# BlueNRG_LP register map
File version: 1.0
CPU: CM0+ r0p0, little endian, no MPU, no FPU, 2 interrupt priority bits
Registers are 32-bit, read-write, reset 0x0 unless marked. A register's access mark holds for its fields unless they carry their own. Offsets are from the block's base; [hi:lo] are bit positions; {n}, {i} and the like mark numbered series.

## IWDG — Independent watchdog
Base 0x40003000
0x00 KR wo — Key register
  [15:0] KEY — Key value (write only, read 0x0000)
0x04 PR — Prescaler register
  [2:0] PR — Prescaler divider
0x08 RLR reset 0xFFF — Reload register
  [11:0] RL — Watchdog counter reload value
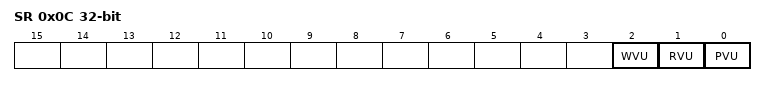
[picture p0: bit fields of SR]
0x0C SR ro — Status register
  [2] WVU — Watchdog counter window prescaler update
  [1] RVU — Watchdog counter reload prescaler update
  [0] PVU — Watchdog prescaler prescaler update
0x10 WINR reset 0xFFF — Window register
  [11:0] WIN — Watchdog counter window value

## LPUART1 — Universal synchronous asynchronous receiver transmitter
Base 0x41005000
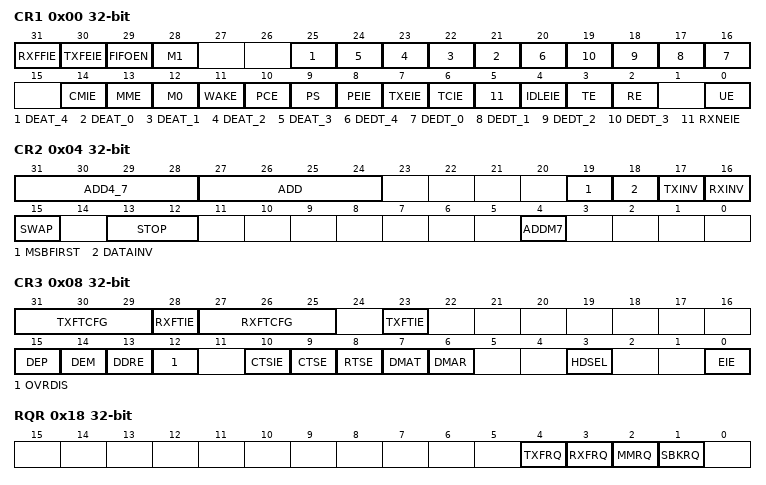
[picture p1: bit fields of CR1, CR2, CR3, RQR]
0x00 CR1 — Control register 1
  [31] RXFFIE
  [30] TXFEIE
  [29] FIFOEN
  [28] M1 — Word length
  [25] DEAT_4 — Driver Enable assertion time
  [n+21] DEAT_{n} (n=0..3)
  [20] DEDT_4 — Driver Enable de-assertion time
  [n+16] DEDT_{n} (n=0..3)
  [14] CMIE — Character match interrupt enable
  [13] MME — Mute mode enable
  [12] M0 — Word length
  [11] WAKE — Receiver wakeup method
  [10] PCE — Parity control enable
  [9] PS — Parity selection
  [8] PEIE — PE interrupt enable
  [7] TXEIE — interrupt enable
  [6] TCIE — Transmission complete interrupt enable
  [5] RXNEIE — RXNE interrupt enable
  [4] IDLEIE — IDLE interrupt enable
  [3] TE — Transmitter enable
  [2] RE — Receiver enable
  [0] UE — USART enable
0x04 CR2 — Control register 2
  [31:28] ADD4_7 — Address of the USART node
  [27:24] ADD — Address of the USART node
  [19] MSBFIRST — Most significant bit first
  [18] DATAINV — Binary data inversion
  [17] TXINV — TX pin active level inversion
  [16] RXINV — RX pin active level inversion
  [15] SWAP — Swap TX/RX pins
  [13:12] STOP — STOP bits
  [4] ADDM7 — 7-bit Address Detection/4-bit address Detection
0x08 CR3 — Control register 3
  [31:29] TXFTCFG — TXFIFO threshold configuration
  [28] RXFTIE
  [27:25] RXFTCFG — Receive FIFO threshold configuration
  [23] TXFTIE — TXFIFO threshold interrupt enable
  [15] DEP — Driver enable polarity selection
  [14] DEM — Driver enable mode
  [13] DDRE — DMA Disable on reception Error
  [12] OVRDIS — Overrun Disable
  [10] CTSIE — CTS interrupt enable
  [9] CTSE — CTS enable
  [8] RTSE — RTS enable
  [7] DMAT — DMA enable transmitter
  [6] DMAR — DMA enable receiver
  [3] HDSEL — Half-duplex selection
  [0] EIE — Error interrupt enable
0x0C BRR — Baud rate register
  [19:0] BRR
0x18 RQR wo — Request register
  [4] TXFRQ
  [3] RXFRQ — Receive data flush request
  [2] MMRQ — Mute mode request
  [1] SBKRQ — Send break request
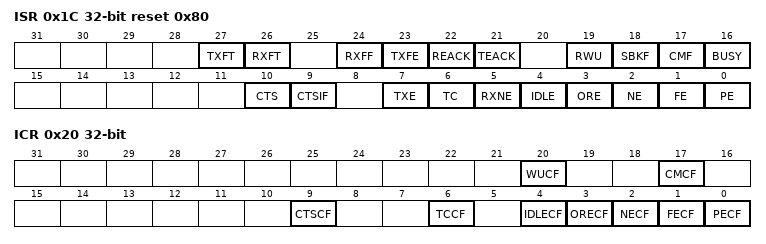
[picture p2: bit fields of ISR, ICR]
0x1C ISR ro reset 0x80 — Interrupt and status register
  [27] TXFT — TXFIFO threshold flag
  [26] RXFT — RXFIFO threshold flag
  [24] RXFF — RXFIFO Full
  [23] TXFE — TXFIFO Empty
  [22] REACK
  [21] TEACK
  [19] RWU
  [18] SBKF
  [17] CMF
  [16] BUSY
  [10] CTS
  [9] CTSIF
  [7] TXE
  [6] TC
  [5] RXNE
  [4] IDLE
  [3] ORE
  [2] NE — START bit Noise detection flag
  [1] FE
  [0] PE
0x20 ICR — Interrupt flag clear register
  [20] WUCF — Wakeup from Stop mode clear flag
  [17] CMCF — Character match clear flag
  [9] CTSCF — CTS clear flag
  [6] TCCF — Transmission complete clear flag
  [4] IDLECF — Idle line detected clear flag
  [3] ORECF — Overrun error clear flag
  [2] NECF — Noise detected clear flag
  [1] FECF — Framing error clear flag
  [0] PECF — Parity error clear flag
0x24 RDR ro — Receive data register
  [8:0] RDR — Receive data value
0x28 TDR — Transmit data register
  [8:0] TDR — Transmit data value
0x2C PRESC — Prescaler register
  [3:0] PRESCALER — Clock prescaler

## PKA
Base 0x48300000
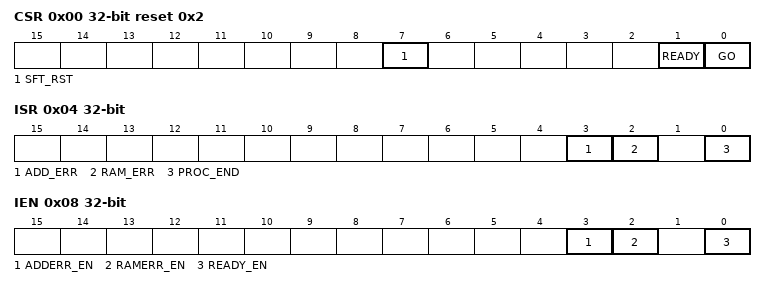
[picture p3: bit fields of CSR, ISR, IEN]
0x00 CSR reset 0x2 — Command and status register
  [7] SFT_RST wo — PKA software reset:<ul><li>0: has no effect.</li><li>1: reset the PKA peripheral.</li></ul>After this bitfield is written to 1, it must be written back to zero manually.
  [1] READY ro — PKA readiness status:<ul><li>0: the PKA is computing. It is not ready.</li><li>1: the PKA is ready to start a new processing.</li></ul>The rising edge of the READY bit set the PROC_END flag in the ISR register.
  [0] GO wo — PKA start processing command:<ul><li>0: has no effect.</li><li>1: starts the processing.</li></ul>After this bitfield is written to 1, it must be written back to zero manually.
0x04 ISR — Interrupt status register
  [3] ADD_ERR — AHB address error interrupt. When read:<ul><li>0: All AHB read or write access to the PKA RAM occurred in a mapped address range.</li><li>1: All AHB read or write access to the PKA RAM occurred in an unmapped address range.</li></ul>When written:<ul><li>0: no effect.</li><li>1: clears the AHB Address error interrupt.</li></ul>
  [2] RAM_ERR — RAM read / write access error interrupt. When read:<ul><li>0: All AHB read or write access to the PKA RAM occurred while the PKA was stopped.</li><li>1: All the AHB read or write access to the PKA RAM occurred while the PKA was operating and using the internal RAM. Those read or write could not succeed as the PKA internal RAM is disconnected from the AHB bus when the PKA is operating (READY bit low).</li></ul>When written:<ul><li>0: no effect.</li><li>1: clears the RAM access error interrupt.</li></ul>
  [0] PROC_END — PKA process ending interrupt. When read:<ul><li>0: no event.</li><li>1: PKA process is ended.</li></ul>When written:<ul><li>0: no effect.</li><li>1: clears the PKA process ending interrupt.</li></ul>
0x08 IEN — Interrupt enable register
  [3] ADDERR_EN — AHB address error interrupt enable.<ul><li>0: interrupt disabled.</li><li>1: interrupt enabled.</li></ul>
  [2] RAMERR_EN — RAM access error interrupt enable.<ul><li>0: interrupt disabled.</li><li>1: interrupt enabled.</li></ul>
  [0] READY_EN
